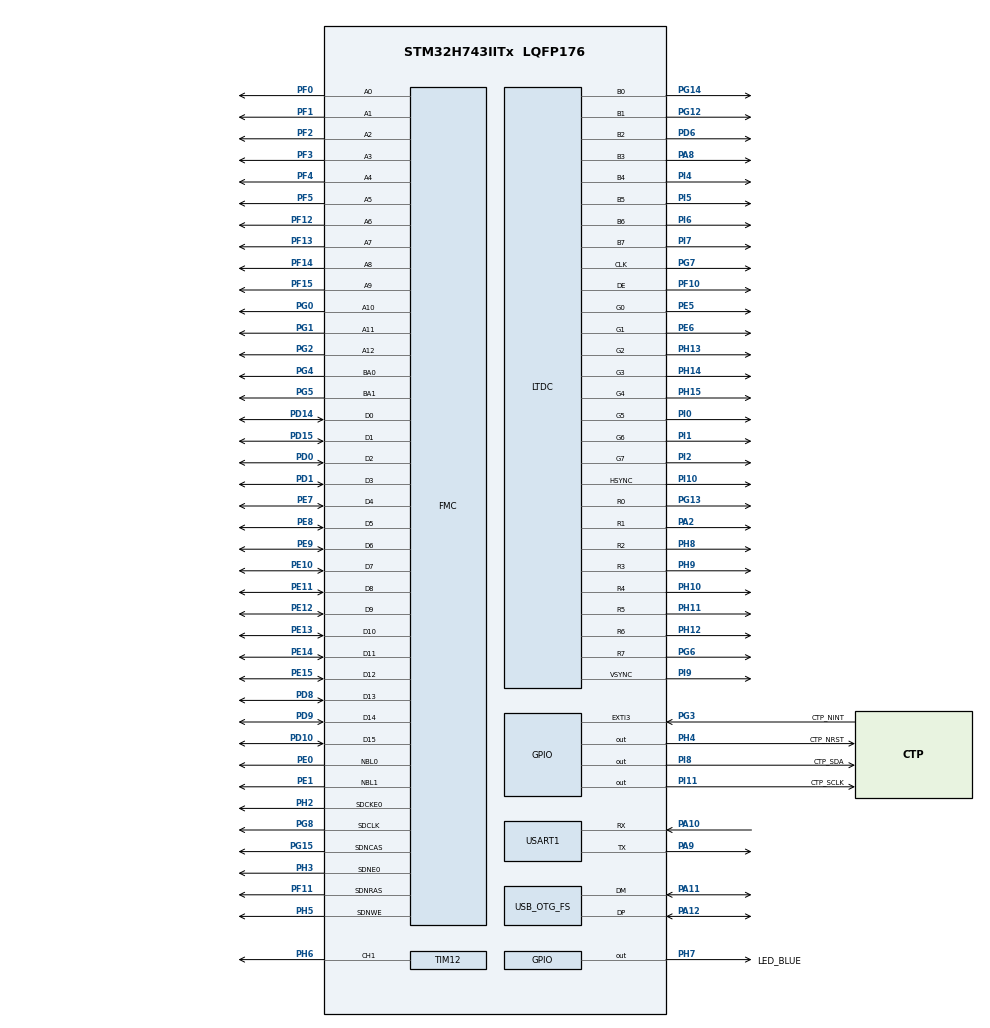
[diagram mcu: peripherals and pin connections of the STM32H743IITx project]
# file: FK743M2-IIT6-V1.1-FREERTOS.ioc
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CORTEX_M7.AccessPermission_S-Cortex_Memory_Protection_Unit_Region1_Settings_S=MPU_REGION_FULL_ACCESS
CORTEX_M7.AccessPermission_Spec=MPU_REGION_FULL_ACCESS
CORTEX_M7.BaseAddress_S-Cortex_Memory_Protection_Unit_Region1_Settings_S=0xC0800000
CORTEX_M7.BaseAddress_Spec=0xC0000000
CORTEX_M7.CPU_DCache=Enabled
CORTEX_M7.CPU_ICache=Enabled
CORTEX_M7.DisableExec_S-Cortex_Memory_Protection_Unit_Region1_Settings_S=MPU_INSTRUCTION_ACCESS_DISABLE
CORTEX_M7.Enable_S-Cortex_Memory_Protection_Unit_Region1_Settings_S=MPU_REGION_ENABLE
CORTEX_M7.Enable_Spec=MPU_REGION_ENABLE
CORTEX_M7.IsBufferable_S-Cortex_Memory_Protection_Unit_Region1_Settings_S=MPU_ACCESS_BUFFERABLE
CORTEX_M7.IsBufferable_Spec=MPU_ACCESS_NOT_BUFFERABLE
CORTEX_M7.IsCacheable_S-Cortex_Memory_Protection_Unit_Region1_Settings_S=MPU_ACCESS_CACHEABLE
CORTEX_M7.IsCacheable_Spec=MPU_ACCESS_CACHEABLE
CORTEX_M7.IsShareable_S-Cortex_Memory_Protection_Unit_Region1_Settings_S=MPU_ACCESS_NOT_SHAREABLE
CORTEX_M7.IsShareable_Spec=MPU_ACCESS_NOT_SHAREABLE
CORTEX_M7.Size_S-Cortex_Memory_Protection_Unit_Region1_Settings_S=MPU_REGION_SIZE_8MB
CORTEX_M7.Size_Spec=MPU_REGION_SIZE_8MB
CORTEX_M7.SubRegionDisable_Spec=0x00
CORTEX_M7.TypeExtField_S-Cortex_Memory_Protection_Unit_Region1_Settings_S=MPU_TEX_LEVEL0
CORTEX_M7.TypeExtField_Spec=MPU_TEX_LEVEL0
CORTEX_M7.default_mode_Activation=1
DMA2D.Mode=DMA2D_M2M_BLEND
FMC.CASLatency1=FMC_SDRAM_CAS_LATENCY_3
FMC.ColumnBitsNumber1=FMC_SDRAM_COLUMN_BITS_NUM_9
FMC.ExitSelfRefreshDelay1=9
FMC.LoadToActiveDelay1=2
FMC.RCDDelay1=2
FMC.RPDelay1=2
FMC.ReadBurst1=FMC_SDRAM_RBURST_ENABLE
FMC.ReadBurst2=FMC_SDRAM_RBURST_ENABLE
FMC.RowCycleDelay1=8
FMC.SDClockPeriod1=FMC_SDRAM_CLOCK_PERIOD_2
FMC.SelfRefreshTime1=6
FMC.WriteRecoveryTime1=4
FREERTOS.Tasks01=defaultTask,24,128,StartDefaultTask,Default,NULL,Dynamic,NULL,NULL
FREERTOS.configENABLE_FPU=1
FREERTOS.configTOTAL_HEAP_SIZE=32768
LTDC.ActiveW=800
LTDC.Alpha_L0=255
LTDC.Alpha_L1=255
LTDC.FBStartAdress_L0=0xC0000000
LTDC.FBStartAdress_L1=0xC0180000
LTDC.HBP=46
LTDC.HFP=210
LTDC.HSync=1
LTDC.ImageHeight_L0=480
LTDC.ImageHeight_L1=480
LTDC.ImageWidth_L0=800
LTDC.Layers=0
LTDC.PixelFormat_L0=LTDC_PIXEL_FORMAT_ARGB8888
LTDC.VBP=23
LTDC.VFP=22
LTDC.VSync=1
LTDC.WindowX1_L0=799
LTDC.WindowX1_L1=799
LTDC.WindowY1_L0=479
LTDC.WindowY1_L1=479
Mcu.Family=STM32H7
Mcu.Name=STM32H743IITx
Mcu.Package=LQFP176
NVIC.DMA2D_IRQn=true\:5\:0\:false\:false\:true\:true\:true\:true\:true
NVIC.EXTI3_IRQn=true\:5\:0\:false\:false\:true\:true\:true\:true\:true
NVIC.LTDC_IRQn=true\:5\:0\:false\:false\:true\:true\:true\:true\:true
NVIC.OTG_FS_IRQn=true\:5\:0\:false\:false\:true\:true\:false\:true\:true
NVIC.PriorityGroup=NVIC_PRIORITYGROUP_4
NVIC.TIM7_IRQn=true\:15\:0\:false\:false\:true\:false\:false\:true\:true
NVIC.TimeBase=TIM7_IRQn
NVIC.TimeBaseIP=TIM7
PA10.Mode=Asynchronous
PA10.Signal=USART1_RX
PA11.Mode=Device_Only
PA11.Signal=USB_OTG_FS_DM
PA12.Mode=Device_Only
PA12.Signal=USB_OTG_FS_DP
PA13\ (JTMS/SWDIO).Mode=Serial_Wire
PA13\ (JTMS/SWDIO).Signal=DEBUG_JTMS-SWDIO
PA14\ (JTCK/SWCLK).Mode=Serial_Wire
PA14\ (JTCK/SWCLK).Signal=DEBUG_JTCK-SWCLK
PA2.Mode=RGB888
PA2.Signal=LTDC_R1
PA8.Mode=RGB888
PA8.Signal=LTDC_B3
PA9.Mode=Asynchronous
PA9.Signal=USART1_TX
PC14-OSC32_IN\ (OSC32_IN).Mode=LSE-External-Oscillator
PC14-OSC32_IN\ (OSC32_IN).Signal=RCC_OSC32_IN
PC15-OSC32_OUT\ (OSC32_OUT).Mode=LSE-External-Oscillator
PC15-OSC32_OUT\ (OSC32_OUT).Signal=RCC_OSC32_OUT
PD0.GPIO_Speed_High_Default=GPIO_SPEED_FREQ_VERY_HIGH
PD0.Signal=FMC_D2_DA2
PD1.GPIO_Speed_High_Default=GPIO_SPEED_FREQ_VERY_HIGH
PD1.Signal=FMC_D3_DA3
PD10.GPIO_Speed_High_Default=GPIO_SPEED_FREQ_VERY_HIGH
PD10.Signal=FMC_D15_DA15
PD14.GPIO_Speed_High_Default=GPIO_SPEED_FREQ_VERY_HIGH
PD14.Signal=FMC_D0_DA0
PD15.GPIO_Speed_High_Default=GPIO_SPEED_FREQ_VERY_HIGH
PD15.Signal=FMC_D1_DA1
PD6.Mode=RGB888
PD6.Signal=LTDC_B2
PD8.GPIO_Speed_High_Default=GPIO_SPEED_FREQ_VERY_HIGH
PD8.Signal=FMC_D13_DA13
PD9.GPIO_Speed_High_Default=GPIO_SPEED_FREQ_VERY_HIGH
PD9.Signal=FMC_D14_DA14
PE0.GPIO_Speed_High_Default=GPIO_SPEED_FREQ_VERY_HIGH
PE0.Signal=FMC_NBL0
PE1.GPIO_Speed_High_Default=GPIO_SPEED_FREQ_VERY_HIGH
PE1.Signal=FMC_NBL1
PE10.GPIO_Speed_High_Default=GPIO_SPEED_FREQ_VERY_HIGH
PE10.Signal=FMC_D7_DA7
PE11.GPIO_Speed_High_Default=GPIO_SPEED_FREQ_VERY_HIGH
PE11.Signal=FMC_D8_DA8
PE12.GPIO_Speed_High_Default=GPIO_SPEED_FREQ_VERY_HIGH
PE12.Signal=FMC_D9_DA9
PE13.GPIO_Speed_High_Default=GPIO_SPEED_FREQ_VERY_HIGH
PE13.Signal=FMC_D10_DA10
PE14.GPIO_Speed_High_Default=GPIO_SPEED_FREQ_VERY_HIGH
PE14.Signal=FMC_D11_DA11
PE15.GPIO_Speed_High_Default=GPIO_SPEED_FREQ_VERY_HIGH
PE15.Signal=FMC_D12_DA12
PE5.Mode=RGB888
PE5.Signal=LTDC_G0
PE6.Mode=RGB888
PE6.Signal=LTDC_G1
PE7.GPIO_Speed_High_Default=GPIO_SPEED_FREQ_VERY_HIGH
PE7.Signal=FMC_D4_DA4
PE8.GPIO_Speed_High_Default=GPIO_SPEED_FREQ_VERY_HIGH
PE8.Signal=FMC_D5_DA5
PE9.GPIO_Speed_High_Default=GPIO_SPEED_FREQ_VERY_HIGH
PE9.Signal=FMC_D6_DA6
PF0.GPIO_Speed_High_Default=GPIO_SPEED_FREQ_VERY_HIGH
PF0.Signal=FMC_A0
PF1.GPIO_Speed_High_Default=GPIO_SPEED_FREQ_VERY_HIGH
PF1.Signal=FMC_A1
PF10.Mode=RGB888
PF10.Signal=LTDC_DE
PF11.GPIO_Speed_High_Default=GPIO_SPEED_FREQ_VERY_HIGH
PF11.Signal=FMC_SDNRAS
PF12.GPIO_Speed_High_Default=GPIO_SPEED_FREQ_VERY_HIGH
PF12.Signal=FMC_A6
PF13.GPIO_Speed_High_Default=GPIO_SPEED_FREQ_VERY_HIGH
PF13.Signal=FMC_A7
PF14.GPIO_Speed_High_Default=GPIO_SPEED_FREQ_VERY_HIGH
PF14.Signal=FMC_A8
PF15.GPIO_Speed_High_Default=GPIO_SPEED_FREQ_VERY_HIGH
PF15.Signal=FMC_A9
PF2.GPIO_Speed_High_Default=GPIO_SPEED_FREQ_VERY_HIGH
PF2.Signal=FMC_A2
PF3.GPIO_Speed_High_Default=GPIO_SPEED_FREQ_VERY_HIGH
PF3.Signal=FMC_A3
PF4.GPIO_Speed_High_Default=GPIO_SPEED_FREQ_VERY_HIGH
PF4.Signal=FMC_A4
PF5.GPIO_Speed_High_Default=GPIO_SPEED_FREQ_VERY_HIGH
PF5.Signal=FMC_A5
PG0.GPIO_Speed_High_Default=GPIO_SPEED_FREQ_VERY_HIGH
PG0.Signal=FMC_A10
PG1.GPIO_Speed_High_Default=GPIO_SPEED_FREQ_VERY_HIGH
PG1.Signal=FMC_A11
PG12.Mode=RGB888
PG12.Signal=LTDC_B1
PG13.Mode=RGB888
PG13.Signal=LTDC_R0
PG14.Mode=RGB888
PG14.Signal=LTDC_B0
PG15.GPIO_Speed_High_Default=GPIO_SPEED_FREQ_VERY_HIGH
PG15.Signal=FMC_SDNCAS
PG2.GPIO_Speed_High_Default=GPIO_SPEED_FREQ_VERY_HIGH
PG2.Signal=FMC_A12
PG3.GPIO_Label=CTP_NINT
PG3.GPIO_ModeDefaultEXTI=GPIO_MODE_IT_FALLING
PG3.GPIO_PuPd=GPIO_PULLUP
PG3.Signal=GPXTI3
PG4.GPIO_Speed_High_Default=GPIO_SPEED_FREQ_VERY_HIGH
PG4.Signal=FMC_A14_BA0
PG5.GPIO_Speed_High_Default=GPIO_SPEED_FREQ_VERY_HIGH
PG5.Signal=FMC_A15_BA1
PG6.Mode=RGB888
PG6.Signal=LTDC_R7
PG7.Mode=RGB888
PG7.Signal=LTDC_CLK
PG8.GPIO_Speed_High_Default=GPIO_SPEED_FREQ_VERY_HIGH
PG8.Signal=FMC_SDCLK
PH0-OSC_IN\ (PH0).Mode=HSE-External-Oscillator
PH0-OSC_IN\ (PH0).Signal=RCC_OSC_IN
PH1-OSC_OUT\ (PH1).Mode=HSE-External-Oscillator
PH1-OSC_OUT\ (PH1).Signal=RCC_OSC_OUT
PH10.Mode=RGB888
PH10.Signal=LTDC_R4
PH11.Mode=RGB888
PH11.Signal=LTDC_R5
PH12.Mode=RGB888
PH12.Signal=LTDC_R6
PH13.Mode=RGB888
PH13.Signal=LTDC_G2
PH14.Mode=RGB888
PH14.Signal=LTDC_G3
PH15.Mode=RGB888
PH15.Signal=LTDC_G4
PH2.GPIO_Speed_High_Default=GPIO_SPEED_FREQ_VERY_HIGH
PH2.Mode=SdramChipSelect1_1
PH2.Signal=FMC_SDCKE0
PH3.GPIO_Speed_High_Default=GPIO_SPEED_FREQ_VERY_HIGH
PH3.Mode=SdramChipSelect1_1
PH3.Signal=FMC_SDNE0
PH4.GPIO_Label=CTP_NRST
PH4.GPIO_PuPd=GPIO_PULLUP
PH4.Signal=GPIO_Output
PH5.GPIO_Speed_High_Default=GPIO_SPEED_FREQ_VERY_HIGH
PH5.Signal=FMC_SDNWE
PH6.Signal=S_TIM12_CH1
PH7.GPIO_Label=LED_BLUE
PH7.Signal=GPIO_Output
PH8.Mode=RGB888
PH8.Signal=LTDC_R2
PH9.Mode=RGB888
PH9.Signal=LTDC_R3
PI0.Mode=RGB888
PI0.Signal=LTDC_G5
PI1.Mode=RGB888
PI1.Signal=LTDC_G6
PI10.Mode=RGB888
PI10.Signal=LTDC_HSYNC
PI11.GPIO_Label=CTP_SCLK
PI11.GPIO_ModeDefaultOutputPP=GPIO_MODE_OUTPUT_OD
PI11.GPIO_PuPd=GPIO_PULLUP
PI11.GPIO_Speed=GPIO_SPEED_FREQ_VERY_HIGH
PI11.PinState=GPIO_PIN_SET
PI11.Signal=GPIO_Output
PI2.Mode=RGB888
PI2.Signal=LTDC_G7
PI4.Mode=RGB888
PI4.Signal=LTDC_B4
PI5.Mode=RGB888
PI5.Signal=LTDC_B5
PI6.Mode=RGB888
PI6.Signal=LTDC_B6
PI7.Mode=RGB888
PI7.Signal=LTDC_B7
PI8.GPIO_Label=CTP_SDA
PI8.GPIO_ModeDefaultOutputPP=GPIO_MODE_OUTPUT_OD
PI8.GPIO_PuPd=GPIO_PULLUP
PI8.GPIO_Speed=GPIO_SPEED_FREQ_LOW
PI8.PinState=GPIO_PIN_SET
PI8.Signal=GPIO_Output
PI9.Mode=RGB888
PI9.Signal=LTDC_VSYNC
ProjectManager.HeapSize=0x200
ProjectManager.StackSize=0x400
ProjectManager.TargetToolchain=Makefile
RCC.ADCFreq_Value=50390625
RCC.APB1Freq_Value=120000000
RCC.APB2Freq_Value=120000000
RCC.APB3Freq_Value=120000000
RCC.APB4Freq_Value=120000000
RCC.CortexFreq_Value=480000000
RCC.D1PPRE=RCC_APB3_DIV2
RCC.D2PPRE1=RCC_APB1_DIV2
RCC.D2PPRE2=RCC_APB2_DIV2
RCC.D3PPRE=RCC_APB4_DIV2
RCC.DIVM1=5
RCC.DIVN1=192
RCC.DIVN3=192
RCC.DIVQ1=20
RCC.DIVR3=6
RCC.HCLKFreq_Value=240000000
RCC.HPRE=RCC_HCLK_DIV2
RCC.PLL2FRACN=0
RCC.PLL3FRACN=0
RCC.PLLFRACN=0
RCC.SYSCLKFreq_VALUE=480000000
RCC.SYSCLKSource=RCC_SYSCLKSOURCE_PLLCLK
RCC.USBFreq_Value=48000000
SH.FMC_A0.0=FMC_A0,13b-sda1
SH.FMC_A1.0=FMC_A1,13b-sda1
SH.FMC_A10.0=FMC_A10,13b-sda1
SH.FMC_A11.0=FMC_A11,13b-sda1
SH.FMC_A12.0=FMC_A12,13b-sda1
SH.FMC_A14_BA0.0=FMC_BA0,FourSdramBanks1
SH.FMC_A15_BA1.0=FMC_BA1,FourSdramBanks1
SH.FMC_A2.0=FMC_A2,13b-sda1
SH.FMC_A3.0=FMC_A3,13b-sda1
SH.FMC_A4.0=FMC_A4,13b-sda1
SH.FMC_A5.0=FMC_A5,13b-sda1
SH.FMC_A6.0=FMC_A6,13b-sda1
SH.FMC_A7.0=FMC_A7,13b-sda1
SH.FMC_A8.0=FMC_A8,13b-sda1
SH.FMC_A9.0=FMC_A9,13b-sda1
SH.FMC_D0_DA0.0=FMC_D0,sd-16b-d1
SH.FMC_D10_DA10.0=FMC_D10,sd-16b-d1
SH.FMC_D11_DA11.0=FMC_D11,sd-16b-d1
SH.FMC_D12_DA12.0=FMC_D12,sd-16b-d1
SH.FMC_D13_DA13.0=FMC_D13,sd-16b-d1
SH.FMC_D14_DA14.0=FMC_D14,sd-16b-d1
SH.FMC_D15_DA15.0=FMC_D15,sd-16b-d1
SH.FMC_D1_DA1.0=FMC_D1,sd-16b-d1
SH.FMC_D2_DA2.0=FMC_D2,sd-16b-d1
SH.FMC_D3_DA3.0=FMC_D3,sd-16b-d1
SH.FMC_D4_DA4.0=FMC_D4,sd-16b-d1
SH.FMC_D5_DA5.0=FMC_D5,sd-16b-d1
SH.FMC_D6_DA6.0=FMC_D6,sd-16b-d1
SH.FMC_D7_DA7.0=FMC_D7,sd-16b-d1
SH.FMC_D8_DA8.0=FMC_D8,sd-16b-d1
SH.FMC_D9_DA9.0=FMC_D9,sd-16b-d1
SH.FMC_NBL0.0=FMC_NBL0,Sd2ByteEnable1
SH.FMC_NBL1.0=FMC_NBL1,Sd2ByteEnable1
SH.FMC_SDCLK.0=FMC_SDCLK,13b-sda1
SH.FMC_SDNCAS.0=FMC_SDNCAS,13b-sda1
SH.FMC_SDNRAS.0=FMC_SDNRAS,13b-sda1
SH.FMC_SDNWE.0=FMC_SDNWE,13b-sda1
SH.S_TIM12_CH1.0=TIM12_CH1,PWM Generation1 CH1
TIM12.AutoReloadPreload=TIM_AUTORELOAD_PRELOAD_ENABLE
TIM12.Channel-PWM\ Generation1\ CH1=TIM_CHANNEL_1
TIM12.Period=999
TIM12.Prescaler=239
TIM12.Pulse-PWM\ Generation1\ CH1=400
USART1.VirtualMode-Asynchronous=VM_ASYNC
USB_DEVICE.CLASS_NAME_FS=CDC
USB_DEVICE.VirtualMode-CDC_FS=Cdc
USB_DEVICE.VirtualModeFS=Cdc_FS
USB_OTG_FS.VirtualMode=Device_Only
VP_DMA2D_VS_DMA2D.Mode=DMA2D_Activate
VP_FREERTOS_VS_CMSIS_V2.Mode=CMSIS_V2
VP_MEMORYMAP_VS_MEMORYMAP.Mode=CurAppReg
VP_SYS_VS_tim7.Mode=TIM7
VP_TIM12_VS_ClockSourceINT.Mode=Internal
VP_USB_DEVICE_VS_USB_DEVICE_CDC_FS.Mode=CDC_FS
board=custom

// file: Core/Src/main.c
/* USER CODE BEGIN Header */
/**
  ******************************************************************************
  * @file           : main.c
  * @brief          : Main program body
  ******************************************************************************
  * @attention
  *
  * Copyright (c) 2026 STMicroelectronics.
  * All rights reserved.
  *
  * This software is licensed under terms that can be found in the LICENSE file
  * in the root directory of this software component.
  * If no LICENSE file comes with this software, it is provided AS-IS.
  *
  ******************************************************************************
  */
/* USER CODE END Header */
#include "main.h"
#include "FreeRTOS.h"
#include "cmsis_os2.h"
#include "usb_device.h"

/* USER CODE BEGIN Includes */
#include "app.h"
/* USER CODE END Includes */

DMA2D_HandleTypeDef hdma2d;

LTDC_HandleTypeDef hltdc;

TIM_HandleTypeDef htim12;

UART_HandleTypeDef huart1;

SDRAM_HandleTypeDef hsdram1;

/* Definitions for defaultTask */
osThreadId_t defaultTaskHandle;
const osThreadAttr_t defaultTask_attributes = {
  .name = "defaultTask",
  .stack_size = 128 * 4,
  .priority = (osPriority_t) osPriorityNormal,
};

void SystemClock_Config(void);
static void MPU_Config(void);
static void MX_GPIO_Init(void);
static void MX_FMC_Init(void);
static void MX_LTDC_Init(void);
static void MX_USART1_UART_Init(void);
static void MX_TIM12_Init(void);
static void MX_DMA2D_Init(void);
void StartDefaultTask(void *argument);

int main(void)
{

  /* MPU Configuration--------------------------------------------------------*/
  MPU_Config();

  /* Enable the CPU Cache */

  /* Enable I-Cache---------------------------------------------------------*/
  SCB_EnableICache();

  /* Enable D-Cache---------------------------------------------------------*/
  SCB_EnableDCache();

  /* MCU Configuration--------------------------------------------------------*/

  /* Reset of all peripherals, Initializes the Flash interface and the Systick. */
  HAL_Init();

  /* Configure the system clock */
  SystemClock_Config();

  /* Initialize all configured peripherals */
  MX_GPIO_Init();
  MX_FMC_Init();
  MX_LTDC_Init();
  MX_USART1_UART_Init();
  MX_TIM12_Init();
  MX_DMA2D_Init();

  /* Init scheduler */
  osKernelInitialize();

  /* Create the thread(s) */
  /* creation of defaultTask */
  defaultTaskHandle = osThreadNew(StartDefaultTask, NULL, &defaultTask_attributes);

  /* USER CODE BEGIN RTOS_THREADS */
  /* add threads, ... */
  app_init();
  /* USER CODE END RTOS_THREADS */

  /* Start scheduler */
  osKernelStart();

  /* We should never get here as control is now taken by the scheduler */

  /* Infinite loop */
  while (1)
  {

  }
}

void SystemClock_Config(void)
{
  RCC_OscInitTypeDef RCC_OscInitStruct = {0};
  RCC_ClkInitTypeDef RCC_ClkInitStruct = {0};

  /** Supply configuration update enable
  */
  HAL_PWREx_ConfigSupply(PWR_LDO_SUPPLY);

  /** Configure the main internal regulator output voltage
  */
  __HAL_PWR_VOLTAGESCALING_CONFIG(PWR_REGULATOR_VOLTAGE_SCALE0);

  while(!__HAL_PWR_GET_FLAG(PWR_FLAG_VOSRDY)) {}

  /** Initializes the RCC Oscillators according to the specified parameters
  * in the RCC_OscInitTypeDef structure.
  */
  RCC_OscInitStruct.OscillatorType = RCC_OSCILLATORTYPE_HSE;
  RCC_OscInitStruct.HSEState = RCC_HSE_ON;
  RCC_OscInitStruct.PLL.PLLState = RCC_PLL_ON;
  RCC_OscInitStruct.PLL.PLLSource = RCC_PLLSOURCE_HSE;
  RCC_OscInitStruct.PLL.PLLM = 5;
  RCC_OscInitStruct.PLL.PLLN = 192;
  RCC_OscInitStruct.PLL.PLLP = 2;
  RCC_OscInitStruct.PLL.PLLQ = 20;
  RCC_OscInitStruct.PLL.PLLR = 2;
  RCC_OscInitStruct.PLL.PLLRGE = RCC_PLL1VCIRANGE_2;
  RCC_OscInitStruct.PLL.PLLVCOSEL = RCC_PLL1VCOWIDE;
  RCC_OscInitStruct.PLL.PLLFRACN = 0;
  if (HAL_RCC_OscConfig(&RCC_OscInitStruct) != HAL_OK)
  {
    Error_Handler();
  }

  /** Initializes the CPU, AHB and APB buses clocks
  */
  RCC_ClkInitStruct.ClockType = RCC_CLOCKTYPE_HCLK|RCC_CLOCKTYPE_SYSCLK
                              |RCC_CLOCKTYPE_PCLK1|RCC_CLOCKTYPE_PCLK2
                              |RCC_CLOCKTYPE_D3PCLK1|RCC_CLOCKTYPE_D1PCLK1;
  RCC_ClkInitStruct.SYSCLKSource = RCC_SYSCLKSOURCE_PLLCLK;
  RCC_ClkInitStruct.SYSCLKDivider = RCC_SYSCLK_DIV1;
  RCC_ClkInitStruct.AHBCLKDivider = RCC_HCLK_DIV2;
  RCC_ClkInitStruct.APB3CLKDivider = RCC_APB3_DIV2;
  RCC_ClkInitStruct.APB1CLKDivider = RCC_APB1_DIV2;
  RCC_ClkInitStruct.APB2CLKDivider = RCC_APB2_DIV2;
  RCC_ClkInitStruct.APB4CLKDivider = RCC_APB4_DIV2;

  if (HAL_RCC_ClockConfig(&RCC_ClkInitStruct, FLASH_LATENCY_4) != HAL_OK)
  {
    Error_Handler();
  }
}

static void MX_DMA2D_Init(void)
{

  hdma2d.Instance = DMA2D;
  hdma2d.Init.Mode = DMA2D_M2M_BLEND;
  hdma2d.Init.ColorMode = DMA2D_OUTPUT_ARGB8888;
  hdma2d.Init.OutputOffset = 0;
  hdma2d.LayerCfg[1].InputOffset = 0;
  hdma2d.LayerCfg[1].InputColorMode = DMA2D_INPUT_ARGB8888;
  hdma2d.LayerCfg[1].AlphaMode = DMA2D_NO_MODIF_ALPHA;
  hdma2d.LayerCfg[1].InputAlpha = 0;
  hdma2d.LayerCfg[1].AlphaInverted = DMA2D_REGULAR_ALPHA;
  hdma2d.LayerCfg[1].RedBlueSwap = DMA2D_RB_REGULAR;
  hdma2d.LayerCfg[1].ChromaSubSampling = DMA2D_NO_CSS;
  hdma2d.LayerCfg[0].InputOffset = 0;
  hdma2d.LayerCfg[0].InputColorMode = DMA2D_INPUT_ARGB8888;
  hdma2d.LayerCfg[0].AlphaMode = DMA2D_NO_MODIF_ALPHA;
  hdma2d.LayerCfg[0].InputAlpha = 0;
  hdma2d.LayerCfg[0].AlphaInverted = DMA2D_REGULAR_ALPHA;
  hdma2d.LayerCfg[0].RedBlueSwap = DMA2D_RB_REGULAR;
  if (HAL_DMA2D_Init(&hdma2d) != HAL_OK)
  {
    Error_Handler();
  }
  if (HAL_DMA2D_ConfigLayer(&hdma2d, 0) != HAL_OK)
  {
    Error_Handler();
  }
  if (HAL_DMA2D_ConfigLayer(&hdma2d, 1) != HAL_OK)
  {
    Error_Handler();
  }

}

static void MX_LTDC_Init(void)
{

  LTDC_LayerCfgTypeDef pLayerCfg = {0};

  hltdc.Instance = LTDC;
  hltdc.Init.HSPolarity = LTDC_HSPOLARITY_AL;
  hltdc.Init.VSPolarity = LTDC_VSPOLARITY_AL;
  hltdc.Init.DEPolarity = LTDC_DEPOLARITY_AL;
  hltdc.Init.PCPolarity = LTDC_PCPOLARITY_IPC;
  hltdc.Init.HorizontalSync = 0;
  hltdc.Init.VerticalSync = 0;
  hltdc.Init.AccumulatedHBP = 46;
  hltdc.Init.AccumulatedVBP = 23;
  hltdc.Init.AccumulatedActiveW = 846;
  hltdc.Init.AccumulatedActiveH = 503;
  hltdc.Init.TotalWidth = 1056;
  hltdc.Init.TotalHeigh = 525;
  hltdc.Init.Backcolor.Blue = 0;
  hltdc.Init.Backcolor.Green = 0;
  hltdc.Init.Backcolor.Red = 0;
  if (HAL_LTDC_Init(&hltdc) != HAL_OK)
  {
    Error_Handler();
  }
  pLayerCfg.WindowX0 = 0;
  pLayerCfg.WindowX1 = 799;
  pLayerCfg.WindowY0 = 0;
  pLayerCfg.WindowY1 = 479;
  pLayerCfg.PixelFormat = LTDC_PIXEL_FORMAT_ARGB8888;
  pLayerCfg.Alpha = 255;
  pLayerCfg.Alpha0 = 0;
  pLayerCfg.BlendingFactor1 = LTDC_BLENDING_FACTOR1_CA;
  pLayerCfg.BlendingFactor2 = LTDC_BLENDING_FACTOR2_CA;
  pLayerCfg.FBStartAdress = 0xC0000000;
  pLayerCfg.ImageWidth = 800;
  pLayerCfg.ImageHeight = 480;
  pLayerCfg.Backcolor.Blue = 0;
  pLayerCfg.Backcolor.Green = 0;
  pLayerCfg.Backcolor.Red = 0;
  if (HAL_LTDC_ConfigLayer(&hltdc, &pLayerCfg, 0) != HAL_OK)
  {
    Error_Handler();
  }

}

static void MX_TIM12_Init(void)
{

  TIM_ClockConfigTypeDef sClockSourceConfig = {0};
  TIM_MasterConfigTypeDef sMasterConfig = {0};
  TIM_OC_InitTypeDef sConfigOC = {0};

  htim12.Instance = TIM12;
  htim12.Init.Prescaler = 239;
  htim12.Init.CounterMode = TIM_COUNTERMODE_UP;
  htim12.Init.Period = 999;
  htim12.Init.ClockDivision = TIM_CLOCKDIVISION_DIV1;
  htim12.Init.AutoReloadPreload = TIM_AUTORELOAD_PRELOAD_ENABLE;
  if (HAL_TIM_Base_Init(&htim12) != HAL_OK)
  {
    Error_Handler();
  }
  sClockSourceConfig.ClockSource = TIM_CLOCKSOURCE_INTERNAL;
  if (HAL_TIM_ConfigClockSource(&htim12, &sClockSourceConfig) != HAL_OK)
  {
    Error_Handler();
  }
  if (HAL_TIM_PWM_Init(&htim12) != HAL_OK)
  {
    Error_Handler();
  }
  sMasterConfig.MasterOutputTrigger = TIM_TRGO_RESET;
  sMasterConfig.MasterSlaveMode = TIM_MASTERSLAVEMODE_DISABLE;
  if (HAL_TIMEx_MasterConfigSynchronization(&htim12, &sMasterConfig) != HAL_OK)
  {
    Error_Handler();
  }
  sConfigOC.OCMode = TIM_OCMODE_PWM1;
  sConfigOC.Pulse = 400;
  sConfigOC.OCPolarity = TIM_OCPOLARITY_HIGH;
  sConfigOC.OCFastMode = TIM_OCFAST_DISABLE;
  if (HAL_TIM_PWM_ConfigChannel(&htim12, &sConfigOC, TIM_CHANNEL_1) != HAL_OK)
  {
    Error_Handler();
  }
  HAL_TIM_MspPostInit(&htim12);

}

static void MX_USART1_UART_Init(void)
{

  huart1.Instance = USART1;
  huart1.Init.BaudRate = 115200;
  huart1.Init.WordLength = UART_WORDLENGTH_8B;
  huart1.Init.StopBits = UART_STOPBITS_1;
  huart1.Init.Parity = UART_PARITY_NONE;
  huart1.Init.Mode = UART_MODE_TX_RX;
  huart1.Init.HwFlowCtl = UART_HWCONTROL_NONE;
  huart1.Init.OverSampling = UART_OVERSAMPLING_16;
  huart1.Init.OneBitSampling = UART_ONE_BIT_SAMPLE_DISABLE;
  huart1.Init.ClockPrescaler = UART_PRESCALER_DIV1;
  huart1.AdvancedInit.AdvFeatureInit = UART_ADVFEATURE_NO_INIT;
  if (HAL_UART_Init(&huart1) != HAL_OK)
  {
    Error_Handler();
  }
  if (HAL_UARTEx_SetTxFifoThreshold(&huart1, UART_TXFIFO_THRESHOLD_1_8) != HAL_OK)
  {
    Error_Handler();
  }
  if (HAL_UARTEx_SetRxFifoThreshold(&huart1, UART_RXFIFO_THRESHOLD_1_8) != HAL_OK)
  {
    Error_Handler();
  }
  if (HAL_UARTEx_DisableFifoMode(&huart1) != HAL_OK)
  {
    Error_Handler();
  }

}

/* FMC initialization function */
static void MX_FMC_Init(void)
{

  FMC_SDRAM_TimingTypeDef SdramTiming = {0};

  /** Perform the SDRAM1 memory initialization sequence
  */
  hsdram1.Instance = FMC_SDRAM_DEVICE;
  /* hsdram1.Init */
  hsdram1.Init.SDBank = FMC_SDRAM_BANK1;
  hsdram1.Init.ColumnBitsNumber = FMC_SDRAM_COLUMN_BITS_NUM_9;
  hsdram1.Init.RowBitsNumber = FMC_SDRAM_ROW_BITS_NUM_13;
  hsdram1.Init.MemoryDataWidth = FMC_SDRAM_MEM_BUS_WIDTH_16;
  hsdram1.Init.InternalBankNumber = FMC_SDRAM_INTERN_BANKS_NUM_4;
  hsdram1.Init.CASLatency = FMC_SDRAM_CAS_LATENCY_3;
  hsdram1.Init.WriteProtection = FMC_SDRAM_WRITE_PROTECTION_DISABLE;
  hsdram1.Init.SDClockPeriod = FMC_SDRAM_CLOCK_PERIOD_2;
  hsdram1.Init.ReadBurst = FMC_SDRAM_RBURST_ENABLE;
  hsdram1.Init.ReadPipeDelay = FMC_SDRAM_RPIPE_DELAY_0;
  /* SdramTiming */
  SdramTiming.LoadToActiveDelay = 2;
  SdramTiming.ExitSelfRefreshDelay = 9;
  SdramTiming.SelfRefreshTime = 6;
  SdramTiming.RowCycleDelay = 8;
  SdramTiming.WriteRecoveryTime = 4;
  SdramTiming.RPDelay = 2;
  SdramTiming.RCDDelay = 2;

  if (HAL_SDRAM_Init(&hsdram1, &SdramTiming) != HAL_OK)
  {
    Error_Handler( );
  }

}

static void MX_GPIO_Init(void)
{
  GPIO_InitTypeDef GPIO_InitStruct = {0};

  /* GPIO Ports Clock Enable */
  __HAL_RCC_GPIOE_CLK_ENABLE();
  __HAL_RCC_GPIOI_CLK_ENABLE();
  __HAL_RCC_GPIOC_CLK_ENABLE();
  __HAL_RCC_GPIOF_CLK_ENABLE();
  __HAL_RCC_GPIOH_CLK_ENABLE();
  __HAL_RCC_GPIOA_CLK_ENABLE();
  __HAL_RCC_GPIOG_CLK_ENABLE();
  __HAL_RCC_GPIOD_CLK_ENABLE();

  /*Configure GPIO pin Output Level */
  HAL_GPIO_WritePin(GPIOI, CTP_SDA_Pin|CTP_SCLK_Pin, GPIO_PIN_SET);

  /*Configure GPIO pin Output Level */
  HAL_GPIO_WritePin(GPIOH, CTP_NRST_Pin|LED_BLUE_Pin, GPIO_PIN_RESET);

  /*Configure GPIO pin : CTP_SDA_Pin */
  GPIO_InitStruct.Pin = CTP_SDA_Pin;
  GPIO_InitStruct.Mode = GPIO_MODE_OUTPUT_OD;
  GPIO_InitStruct.Pull = GPIO_PULLUP;
  GPIO_InitStruct.Speed = GPIO_SPEED_FREQ_LOW;
  HAL_GPIO_Init(CTP_SDA_GPIO_Port, &GPIO_InitStruct);

  /*Configure GPIO pin : CTP_SCLK_Pin */
  GPIO_InitStruct.Pin = CTP_SCLK_Pin;
  GPIO_InitStruct.Mode = GPIO_MODE_OUTPUT_OD;
  GPIO_InitStruct.Pull = GPIO_PULLUP;
  GPIO_InitStruct.Speed = GPIO_SPEED_FREQ_VERY_HIGH;
  HAL_GPIO_Init(CTP_SCLK_GPIO_Port, &GPIO_InitStruct);

  /*Configure GPIO pin : CTP_NRST_Pin */
  GPIO_InitStruct.Pin = CTP_NRST_Pin;
  GPIO_InitStruct.Mode = GPIO_MODE_OUTPUT_PP;
  GPIO_InitStruct.Pull = GPIO_PULLUP;
  GPIO_InitStruct.Speed = GPIO_SPEED_FREQ_LOW;
  HAL_GPIO_Init(CTP_NRST_GPIO_Port, &GPIO_InitStruct);

  /*Configure GPIO pin : LED_BLUE_Pin */
  GPIO_InitStruct.Pin = LED_BLUE_Pin;
  GPIO_InitStruct.Mode = GPIO_MODE_OUTPUT_PP;
  GPIO_InitStruct.Pull = GPIO_NOPULL;
  GPIO_InitStruct.Speed = GPIO_SPEED_FREQ_LOW;
  HAL_GPIO_Init(LED_BLUE_GPIO_Port, &GPIO_InitStruct);

  /*Configure GPIO pin : CTP_NINT_Pin */
  GPIO_InitStruct.Pin = CTP_NINT_Pin;
  GPIO_InitStruct.Mode = GPIO_MODE_IT_FALLING;
  GPIO_InitStruct.Pull = GPIO_PULLUP;
  HAL_GPIO_Init(CTP_NINT_GPIO_Port, &GPIO_InitStruct);

  /* EXTI interrupt init*/
  HAL_NVIC_SetPriority(CTP_NINT_EXTI_IRQn, 5, 0);
  HAL_NVIC_EnableIRQ(CTP_NINT_EXTI_IRQn);

}

void StartDefaultTask(void *argument)
{
  /* init code for USB_DEVICE */
  MX_USB_DEVICE_Init();
  for(;;)
  {
    osDelay(1);
  }
}

 /* MPU Configuration */

void MPU_Config(void)
{
  MPU_Region_InitTypeDef MPU_InitStruct = {0};

  /* Disables the MPU */
  HAL_MPU_Disable();

  /** Initializes and configures the Region and the memory to be protected
  */
  MPU_InitStruct.Enable = MPU_REGION_ENABLE;
  MPU_InitStruct.Number = MPU_REGION_NUMBER0;
  MPU_InitStruct.BaseAddress = 0xC0000000;
  MPU_InitStruct.Size = MPU_REGION_SIZE_8MB;
  MPU_InitStruct.SubRegionDisable = 0x00;
  MPU_InitStruct.TypeExtField = MPU_TEX_LEVEL0;
  MPU_InitStruct.AccessPermission = MPU_REGION_FULL_ACCESS;
  MPU_InitStruct.DisableExec = MPU_INSTRUCTION_ACCESS_DISABLE;
  MPU_InitStruct.IsShareable = MPU_ACCESS_NOT_SHAREABLE;
  MPU_InitStruct.IsCacheable = MPU_ACCESS_CACHEABLE;
  MPU_InitStruct.IsBufferable = MPU_ACCESS_NOT_BUFFERABLE;

  HAL_MPU_ConfigRegion(&MPU_InitStruct);

  /** Initializes and configures the Region and the memory to be protected
  */
  MPU_InitStruct.Number = MPU_REGION_NUMBER1;
  MPU_InitStruct.BaseAddress = 0xC0800000;
  MPU_InitStruct.SubRegionDisable = 0x0;
  MPU_InitStruct.IsBufferable = MPU_ACCESS_BUFFERABLE;

  HAL_MPU_ConfigRegion(&MPU_InitStruct);
  /* Enables the MPU */
  HAL_MPU_Enable(MPU_PRIVILEGED_DEFAULT);

}

void HAL_TIM_PeriodElapsedCallback(TIM_HandleTypeDef *htim)
{
  if (htim->Instance == TIM7)
  {
    HAL_IncTick();
  }
}

void Error_Handler(void)
{
  __disable_irq();
  while (1)
  {
  }
}
#ifdef USE_FULL_ASSERT
/**
  * @brief  Reports the name of the source file and the source line number
  *         where the assert_param error has occurred.
  * @param  file: pointer to the source file name
  * @param  line: assert_param error line source number
  * @retval None
  */
void assert_failed(uint8_t *file, uint32_t line)
{
  /* USER CODE BEGIN 6 */
  /* User can add his own implementation to report the file name and line number, */
  // printf("Wrong parameters value: file %s on line %d\r\n", file, line)
  /* USER CODE END 6 */
}
#endif /* USE_FULL_ASSERT */
